# AC784x register map
Vendor: AutoChips; Series: AC78; File version: 1.0
CPU: CM4 r0p1, little endian, MPU, FPU, VTOR, 4 interrupt priority bits
Registers are 32-bit, read-write, reset 0x0 unless marked. A register's access mark holds for its fields unless they carry their own. Offsets are from the block's base; [hi:lo] are bit positions; {n}, {i} and the like mark numbered series; 'fields as' and 'values as' point back to an identical list.

## CKGEN — Clock Generator
Base 0x40000000
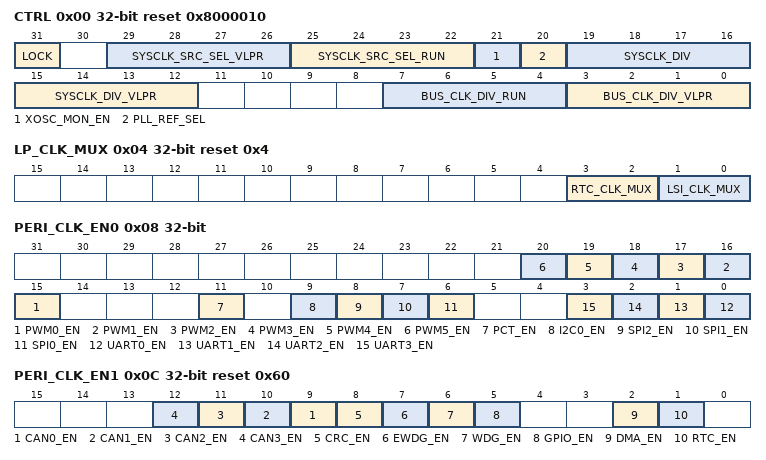
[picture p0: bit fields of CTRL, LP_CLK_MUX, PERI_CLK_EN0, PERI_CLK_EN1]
0x00 CTRL reset 0x8000010 — CKGEN Control Register
  [31] LOCK — Register Lock Enable
    0=LOCK Function Disable; 1=LOCK Function Enable
  [29:26] SYSCLK_SRC_SEL_VLPR — System clock source select in VLPR mode
    2=HSI Clock
  [25:22] SYSCLK_SRC_SEL_RUN — System clock source select in RUN mode
    0=VHSI Clock; 1=HSE Clock; 2=HSI Clock; 3=PLL Clock
  [21] XOSC_MON_EN — XOSC Monitor Function Enable
    0=Monitor Function Disable; 1=Monitor Function Enable
  [20] PLL_REF_SEL — PLL Reference Clock Select
    0=HSI; 1=HSE
  [19:16] SYSCLK_DIV — System Clock Divider in RUN mode
    {v}=divider by {v+1} (v=0..15)
  [15:12] SYSCLK_DIV_VLPR — System Clock Divider in VLPR mode
    {v}=divider by {v+1} (v=0..15)
  [7:4] BUS_CLK_DIV_RUN — Bus Clock divider in RUN mode
    {v}=divider by {v+1} (v=0..15)
  [3:0] BUS_CLK_DIV_VLPR — Bus Clock divider in VLPR mode
    {v}=divider by {v+1} (v=0..15)
0x04 LP_CLK_MUX reset 0x4 — RTC LSI Clock Mux
  [3:2] RTC_CLK_MUX — RTC Clock Source Select
    0=HSEDIV1 Clock; 1=VHSIDIV1 Clock; 2=LSI_32KHz Clock; 3=RTC_CLOCK_IN
  [1:0] LSI_CLK_MUX — LSI Clock Source Select
    0=LSI_128KHz Clock; 1=LSI_32KHz Clock; 2=LSI_1KHz Clock; 3=Reserve
0x08 PERI_CLK_EN0 — Periph Clock Enable Control 0
  [all] fields
    0=Clock Disable; 1=Clock Enable
  [n+15] PWM{n}_EN (n=0..5) — PWM{n} BUS Clock Enable
  [11] PCT_EN — PCT BUS Clock Enable
  [9] I2C0_EN — I2C0 BUS Clock Enable
  [8] SPI2_EN — SPI2 BUS Clock Enable
  [7] SPI1_EN — SPI1 BUS Clock Enable
  [6] SPI0_EN — SPI0 BUS Clock Enable
  [n] UART{n}_EN (n=0..3) — UART{n} BUS Clock Enable
0x0C PERI_CLK_EN1 reset 0x60 — Periph Clock Enable Control 1
  [all] fields
    0=Clock Disable; 1=Clock Enable
  [n+9] CAN{n}_EN (n=0..3) — CAN{n} BUS Clock Enable
  [8] CRC_EN — CRC BUS Clock Enable
  [7] EWDG_EN — EWDG BUS Clock Enable
  [6] WDG_EN — WDG BUS Clock Enable
  [5] GPIO_EN — GPIO AHB Clock Enable
  [2] DMA_EN — DMA BUS Clock Enable
  [1] RTC_EN — RTC BUS Clock Enable
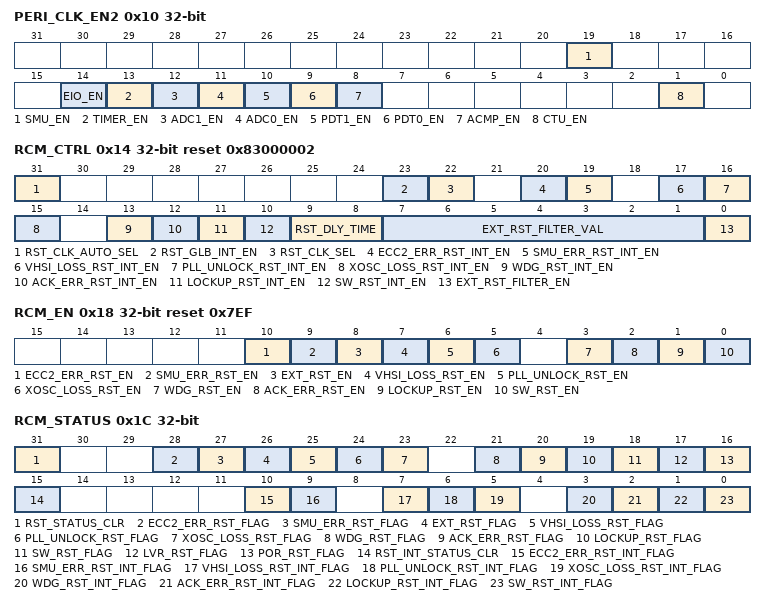
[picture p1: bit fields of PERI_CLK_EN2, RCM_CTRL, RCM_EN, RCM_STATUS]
0x10 PERI_CLK_EN2 — Periph Clock Enable Control 2
  [all] fields
    0=Clock Disable; 1=Clock Enable
  [19] SMU_EN — SMU BUS Clock Enable
  [14] EIO_EN — EIO BUS Clock Enable
  [13] TIMER_EN — TIMER BUS Clock Enable
  [12] ADC1_EN — ADC1 BUS Clock Enable
  [11] ADC0_EN — ADC0 BUS Clock Enable
  [10] PDT1_EN — PDT1 BUS Clock Enable
  [9] PDT0_EN — PDT0 BUS Clock Enable
  [8] ACMP_EN — ACMP BUS Clock Enable
  [1] CTU_EN — CTU BUS Clock Enable
0x14 RCM_CTRL reset 0x83000002 — MCU Reset Control
  [31] RST_CLK_AUTO_SEL — Reset Clock Source Auto Select Configure
    0=Use bit22 to manually switch; 1=Clock switch is automatically
  [23] RST_GLB_INT_EN — Global Reset Interrupt Enable
    0=Disable; 1=Enable
  [22] RST_CLK_SEL — Reset Clock Source Select
    0=Use Internal 128KHz as clock source; 1=Use Internal 8MHz as clock source
  [20] ECC2_ERR_RST_INT_EN — ECC 2bit Error Reset Interrupt Enable
    0=Disable; 1=Enable
  [19] SMU_ERR_RST_INT_EN — SMU Error Reset Interrupt Enable
    0=Disable; 1=Enable
  [17] VHSI_LOSS_RST_INT_EN — VHSI Loss Reset Interrupt Enable
    0=Disable; 1=Enable
  [16] PLL_UNLOCK_RST_INT_EN — PLL Unlock Reset Interrupt Enable
    0=Disable; 1=Enable
  [15] XOSC_LOSS_RST_INT_EN — XOSC Loss Reset Interrupt Enable
    0=Disable; 1=Enable
  [13] WDG_RST_INT_EN — WDG Reset Interrupt Enable
    0=Disable; 1=Enable
  [12] ACK_ERR_RST_INT_EN — ACK Error Reset Interrupt Enable
    0=Disable; 1=Enable
  [11] LOCKUP_RST_INT_EN — Lockup Reset Interrupt Enable
    0=Disable; 1=Enable
  [10] SW_RST_INT_EN — Software Reset Interrupt Enable
    0=Disable; 1=Enable
  [9:8] RST_DLY_TIME — Reset Delay Time Set
    0=8*LPI128K; 1=32*LPI128K; 2=128*LPI128K; 3=512*LPI128K
  [7:1] EXT_RST_FILTER_VAL — EXT Reset Filter Value Set
  [0] EXT_RST_FILTER_EN — EXT Reset Filter Enable
    0=Filter Disable; 1=Filter Enable
0x18 RCM_EN reset 0x7EF — MCU Reset Enable Control
  [all] fields
    0=Disable; 1=Enable
  [10] ECC2_ERR_RST_EN — ECC 2bit Error Reset Enable
  [9] SMU_ERR_RST_EN — SMU Error Reset Enable
  [8] EXT_RST_EN — External Reset Enable
  [7] VHSI_LOSS_RST_EN — VHSI Loss Reset Enable
  [6] PLL_UNLOCK_RST_EN — PLL Unlock Reset Enable
  [5] XOSC_LOSS_RST_EN — XOSC Loss Reset Enable
  [3] WDG_RST_EN — WDG Reset Enable
  [2] ACK_ERR_RST_EN — ACK Error Reset Enable
  [1] LOCKUP_RST_EN — Lockup Reset Enable
  [0] SW_RST_EN — Software Reset Enable
0x1C RCM_STATUS — MCU Reset Status
  [31] RST_STATUS_CLR — Clear All Reset Status
    0=reset update; 1=clear all reset status
  [28] ECC2_ERR_RST_FLAG ro — ECC 2bit Error Reset Flag
    0=Reset Not Happen; 1=Reset Happen
  [27] SMU_ERR_RST_FLAG ro — SMU Error Reset Flag
    0=Reset Not Happen; 1=Reset Happen
  [26] EXT_RST_FLAG ro — Extern Reset Status
    0=Reset Not Happen; 1=Reset Happen
  [25] VHSI_LOSS_RST_FLAG ro — VHSI Loss Reset Flag
    0=Reset Not Happen; 1=Reset Happen
  [24] PLL_UNLOCK_RST_FLAG ro — PLL Unlock Reset Flag
    0=Reset Not Happen; 1=Reset Happen
  [23] XOSC_LOSS_RST_FLAG ro — XOSC Loss Reset Flag
    0=Reset Not Happen; 1=Reset Happen
  [21] WDG_RST_FLAG ro — WDG Reset Flag
    0=Reset Not Happen; 1=Reset Happen
  [20] ACK_ERR_RST_FLAG ro — ACK Error Reset Flag
    0=Reset Not Happen; 1=Reset Happen
  [19] LOCKUP_RST_FLAG ro — Lockup Reset Flag
    0=Reset Not Happen; 1=Reset Happen
  [18] SW_RST_FLAG ro — Software Reset Flag
    0=Reset Not Happen; 1=Reset Happen
  [17] LVR_RST_FLAG ro — Low Voltage Reset Flag
    0=Reset Not Happen; 1=Reset Happen
  [16] POR_RST_FLAG ro — Power on Reset Flag
    0=Reset Not Happen; 1=Reset Happen
  [15] RST_INT_STATUS_CLR — clear All Reset Interrupt Status
    0=reset update; 1=clear all reset status
  [10] ECC2_ERR_RST_INT_FLAG ro — ECC 2bit Error Reset Interrupt Flag
    0=Reset Not Happen; 1=Reset Happen
  [9] SMU_ERR_RST_INT_FLAG ro — SMU Error Reset Interrupt Flag
    0=Reset Not Happen; 1=Reset Happen
  [7] VHSI_LOSS_RST_INT_FLAG ro — VHSI Loss Reset Interrupt Flag
    0=Reset Not Happen; 1=Reset Happen
  [6] PLL_UNLOCK_RST_INT_FLAG ro — PLL Unlock Reset Interrupt Flag
    0=Reset Not Happen; 1=Reset Happen
  [5] XOSC_LOSS_RST_INT_FLAG ro — XOSC Loss Reset Interrupt Flag
    0=Reset Not Happen; 1=Reset Happen
  [3] WDG_RST_INT_FLAG ro — WDG Reset Interrupt Flag
    0=Reset Not Happen; 1=Reset Happen
  [2] ACK_ERR_RST_INT_FLAG ro — ACK Error Reset Interrupt Flag
    0=Reset Not Happen; 1=Reset Happen
  [1] LOCKUP_RST_INT_FLAG ro — Lockup Reset Interrupt Flag
    0=Reset Not Happen; 1=Reset Happen
  [0] SW_RST_INT_FLAG ro — Software Reset Interrupt Flag
    0=Reset Not Happen; 1=Reset Happen
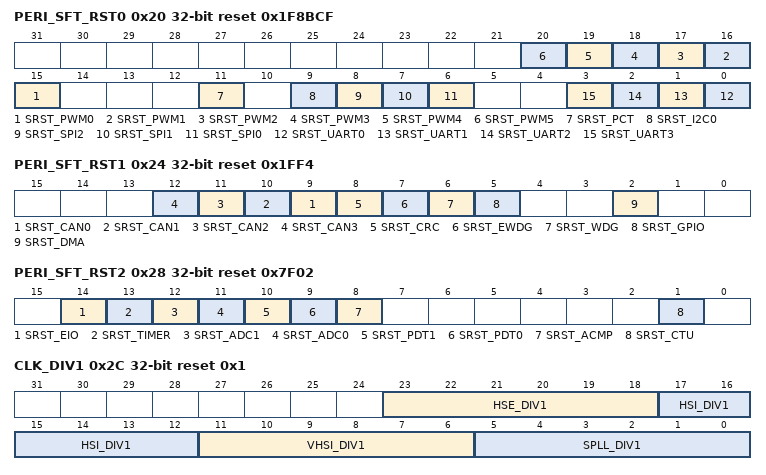
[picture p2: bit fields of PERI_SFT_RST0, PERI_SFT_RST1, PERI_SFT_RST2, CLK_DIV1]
0x20 PERI_SFT_RST0 reset 0x1F8BCF — Periph Software Reset Control 0
  [all] fields
    0=Reset Active; 1=Reset Inactive
  [n+15] SRST_PWM{n} (n=0..5) — PWM{n} Software Reset
  [11] SRST_PCT — PCT Software Reset
  [9] SRST_I2C0 — I2C0 Software Reset
  [8] SRST_SPI2 — SPI2 Software Reset
  [7] SRST_SPI1 — SPI1 Software Reset
  [6] SRST_SPI0 — SPI0 Software Reset
  [n] SRST_UART{n} (n=0..3) — UART{n} Software Reset
0x24 PERI_SFT_RST1 reset 0x1FF4 — Periph Software Reset Control 1
  [all] fields
    0=Reset Active; 1=Reset Inactive
  [n+9] SRST_CAN{n} (n=0..3) — CAN{n} Software Reset
  [8] SRST_CRC — CRC Software Reset
  [7] SRST_EWDG — EWDG Software Reset
  [6] SRST_WDG — WDG Software Reset
  [5] SRST_GPIO — GPIO Software AHB Reset
  [2] SRST_DMA — DMA Software Reset
0x28 PERI_SFT_RST2 reset 0x7F02 — Periph Software Reset Control 2
  [all] fields
    0=Reset Active; 1=Reset Inactive
  [14] SRST_EIO — EIO Software Reset
  [13] SRST_TIMER — TIMER Software Reset
  [12] SRST_ADC1 — ADC1 Software Reset
  [11] SRST_ADC0 — ADC0 Software Reset
  [10] SRST_PDT1 — PDT1 Software Reset
  [9] SRST_PDT0 — PDT0 Software Reset
  [8] SRST_ACMP — ACMP Software Reset
  [1] SRST_CTU — CTU Software Reset
0x2C CLK_DIV1 reset 0x1 — Clock Divider 1
  [23:18] HSE_DIV1 — HSE Clock divider 1
  [17:12] HSI_DIV1 — HSI Clock divider 1
  [11:6] VHSI_DIV1 — VHSI Clock divider 1
  [5:0] SPLL_DIV1 — PLL Clock divider 1
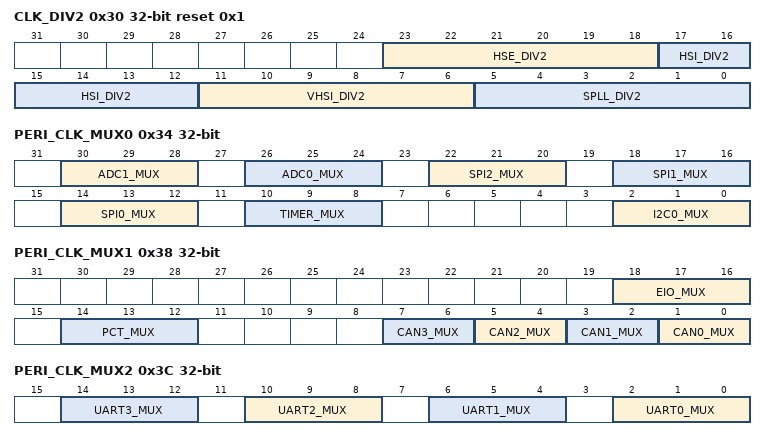
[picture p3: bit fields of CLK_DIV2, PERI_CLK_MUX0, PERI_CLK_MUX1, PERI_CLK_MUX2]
0x30 CLK_DIV2 reset 0x1 — Clock Divider 2
  [23:18] HSE_DIV2 — HSE Clock divider 2
  [17:12] HSI_DIV2 — HSI Clock divider 2
  [11:6] VHSI_DIV2 — VHSI Clock divider 2
  [5:0] SPLL_DIV2 — PLL Clock divider 2
0x34 PERI_CLK_MUX0 — Peripheral Clock MUX0 Register
  [all] fields
    0b0XX=NONE_CLK; 4=HSEDIV2_CLK; 5=HSIDIV2_CLK; 6=VHSIDIV2_CLK; 7=SPLLDIV2_CLK
  [30:28] ADC1_MUX — ADC1 Clock MUX
  [26:24] ADC0_MUX — ADC0 Clock MUX
  [22:20] SPI2_MUX — SPI2 Clock MUX
  [18:16] SPI1_MUX — SPI1 Clock MUX
  [14:12] SPI0_MUX — SPI0 Clock MUX
  [10:8] TIMER_MUX — TIMER Clock MUX
  [2:0] I2C0_MUX — I2C0 Clock MUX
0x38 PERI_CLK_MUX1 — Peripheral Clock MUX1 Register
  [18:16] EIO_MUX — EIO Clock MUX
    values as the fields of PERI_CLK_MUX0
  [14:12] PCT_MUX — PCT Clock MUX
    values as the fields of PERI_CLK_MUX0
  [2n+1:2n] CAN{n}_MUX (n=0..3) — CAN{n} Clock MUX
    0=NONE_CLK; 1=HSEDIV2_CLK; 2=SYS_CLK; 3=SPLLDIV2_CLK
0x3C PERI_CLK_MUX2 — Peripheral Clock MUX2 Register
  [all] fields
    values as the fields of PERI_CLK_MUX0
  [4n+2:4n] UART{n}_MUX (n=0..3) — UART{n} Clock MUX
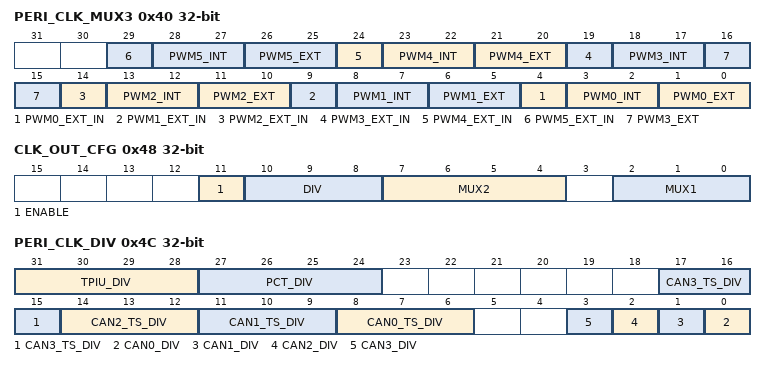
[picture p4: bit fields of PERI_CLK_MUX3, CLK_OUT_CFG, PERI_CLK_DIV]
0x40 PERI_CLK_MUX3 — Peripheral Clock MUX3 Register
  [5n+4] PWM{n}_EXT_IN (n=0..5) — PWM{n} External or Internal Clock Select
    0=INTERNAL_CLK; 1=EXTERNAL_CLK
  [5n+3:5n+2] PWM{n}_INT (n=0..5) — PWM{n} Internal Clock
    0=HSEDIV1_CLK; 1=HSIDIV1_CLK; 2=VHSIDIV1_CLK; 3=SPLLDIV1_CLK
  [5n+1:5n] PWM{n}_EXT (n=0..5) — PWM{n} External Clock
    0=TCLK0_CLK; 1=TCLK1_CLK; 2=TCLK2_CLK; 3=RESERVE
0x48 CLK_OUT_CFG — Clock Out Configure
  [11] ENABLE — Clock Out Enable
    0=DISABLE; 1=ENABLE
  [10:8] DIV — Clock Out Divider
    {v}=divider by {v+1} (v=0..7)
  [7:4] MUX2 — Clock Out MUX2
    0=CLK_OUT_MUX1; 1=RTC_CLK; 2=LSI_CLK; 3=LSI128K_CLK; 4=HSEDIV2_CLK; 5=VHSIDIV2_CLK; 6=HSIDIV2_CLK; 7=SPLLDIV2_CLK; 8=BUS_CLK; 9=FLASH_CLK; 10=AHB_CLK
  [2:0] MUX1 — Clock Out MUX1
    0=HSE_CLK; 1=HSI_CLK; 2=VHSI_CLK; 3=SPLL_CLK; 4=FLASH_CLK
0x4C PERI_CLK_DIV — Peripheral Clock Divider
  [31:28] TPIU_DIV — TPIU Clock Divider
    {v}=divider by {v+1} (v=0..15)
  [27:24] PCT_DIV — PCT Timer Clock Divider
    {v}=divider by {v+1} (v=0..15)
  [3n+8:3n+6] CAN{n}_TS_DIV (n=0..3) — CAN{n} Time Stamp Clock Divider
    {v}=divider by {v+1} (v=0..7)
  [n] CAN{n}_DIV (n=0..3) — CAN{n} Function Clock Divider
    0=divider by 1; 1=divider by 2
